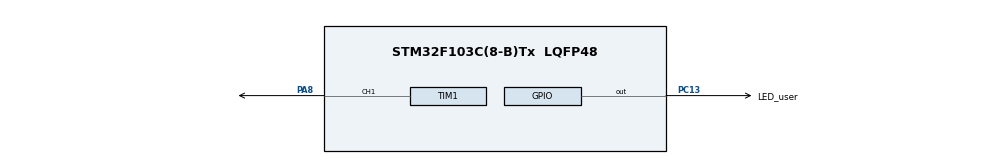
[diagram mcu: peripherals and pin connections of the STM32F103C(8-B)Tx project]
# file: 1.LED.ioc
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Mcu.Family=STM32F1
Mcu.Name=STM32F103C(8-B)Tx
Mcu.Package=LQFP48
NVIC.PriorityGroup=NVIC_PRIORITYGROUP_4
PA13.Mode=Serial_Wire
PA13.Signal=SYS_JTMS-SWDIO
PA14.Mode=Serial_Wire
PA14.Signal=SYS_JTCK-SWCLK
PA8.Signal=S_TIM1_CH1
PC13-TAMPER-RTC.GPIO_Label=LED_user
PC13-TAMPER-RTC.PinState=GPIO_PIN_SET
PC13-TAMPER-RTC.Signal=GPIO_Output
PD0-OSC_IN.Mode=HSE-External-Oscillator
PD0-OSC_IN.Signal=RCC_OSC_IN
PD1-OSC_OUT.Mode=HSE-External-Oscillator
PD1-OSC_OUT.Signal=RCC_OSC_OUT
ProjectManager.HeapSize=0x200
ProjectManager.StackSize=0x400
ProjectManager.TargetToolchain=MDK-ARM V5.32
RCC.AHBFreq_Value=72000000
RCC.APB1CLKDivider=RCC_HCLK_DIV2
RCC.APB1Freq_Value=36000000
RCC.APB1TimFreq_Value=72000000
RCC.APB2Freq_Value=72000000
RCC.APB2TimFreq_Value=72000000
RCC.HCLKFreq_Value=72000000
RCC.PLLMUL=RCC_PLL_MUL9
RCC.PLLSourceVirtual=RCC_PLLSOURCE_HSE
RCC.SYSCLKFreq_VALUE=72000000
RCC.SYSCLKSource=RCC_SYSCLKSOURCE_PLLCLK
RCC.USBFreq_Value=72000000
SH.S_TIM1_CH1.0=TIM1_CH1,PWM Generation1 CH1
TIM1.Channel-PWM\ Generation1\ CH1=TIM_CHANNEL_1
TIM1.Period=99
TIM1.Prescaler=71
VP_TIM1_VS_ClockSourceINT.Mode=Internal
board=custom

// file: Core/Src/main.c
/* USER CODE BEGIN Header */
/**
 ******************************************************************************
 * @file           : main.c
 * @brief          : Main program body
 ******************************************************************************
 * @attention
 *
 * Copyright (c) 2024 STMicroelectronics.
 * All rights reserved.
 *
 * This software is licensed under terms that can be found in the LICENSE file
 * in the root directory of this software component.
 * If no LICENSE file comes with this software, it is provided AS-IS.
 *
 ******************************************************************************
 */
/* USER CODE END Header */
#include "main.h"
#include "tim.h"
#include "gpio.h"

void SystemClock_Config(void);

int main(void)
{

  /* MCU Configuration--------------------------------------------------------*/

  /* Reset of all peripherals, Initializes the Flash interface and the Systick. */
  LL_APB2_GRP1_EnableClock(LL_APB2_GRP1_PERIPH_AFIO);
  LL_APB1_GRP1_EnableClock(LL_APB1_GRP1_PERIPH_PWR);

  /* System interrupt init*/
  NVIC_SetPriorityGrouping(NVIC_PRIORITYGROUP_4);

  /* SysTick_IRQn interrupt configuration */
  NVIC_SetPriority(SysTick_IRQn, NVIC_EncodePriority(NVIC_GetPriorityGrouping(), 15, 0));

  /** NOJTAG: JTAG-DP Disabled and SW-DP Enabled
   */
  LL_GPIO_AF_Remap_SWJ_NOJTAG();

  /* Configure the system clock */
  SystemClock_Config();

  /* Initialize all configured peripherals */
  MX_GPIO_Init();
  MX_TIM1_Init();
  /* USER CODE BEGIN 2 */
  LL_TIM_EnableCounter(TIM1);                        // 启用TIM1的计数器
  LL_TIM_CC_EnableChannel(TIM1, LL_TIM_CHANNEL_CH1); // 启用定时器的指定通道
  LL_TIM_EnableAllOutputs(TIM1);                     // 启用定时器的所有输出，经过测试，不加该语句无法输出PWM

  LL_TIM_OC_SetCompareCH1(TIM1, 50); // 使用函数输出占空比为50的PWM
  // TIM1->CCR1 = 50; // 直接写寄存器的CCR值，输出PWM
  /* USER CODE END 2 */

  /* Infinite loop */
  /* USER CODE BEGIN WHILE */
  while (1)
  {
    // 呼吸灯程序
    for (uint16_t i = 0; i <= 100; i++)
    {
      LL_TIM_OC_SetCompareCH1(TIM1, i); // 输出占空比为i的PWM
      LL_mDelay(50);
    }
    for (uint16_t i = 0; i <= 100; i++)
    {
      LL_TIM_OC_SetCompareCH1(TIM1, 100 - i);
      LL_mDelay(50);
    }
    /* USER CODE END WHILE */

  }
}

void SystemClock_Config(void)
{
  LL_FLASH_SetLatency(LL_FLASH_LATENCY_2);
  while (LL_FLASH_GetLatency() != LL_FLASH_LATENCY_2)
  {
  }
  LL_RCC_HSE_Enable();

  /* Wait till HSE is ready */
  while (LL_RCC_HSE_IsReady() != 1)
  {
  }
  LL_RCC_PLL_ConfigDomain_SYS(LL_RCC_PLLSOURCE_HSE_DIV_1, LL_RCC_PLL_MUL_9);
  LL_RCC_PLL_Enable();

  /* Wait till PLL is ready */
  while (LL_RCC_PLL_IsReady() != 1)
  {
  }
  LL_RCC_SetAHBPrescaler(LL_RCC_SYSCLK_DIV_1);
  LL_RCC_SetAPB1Prescaler(LL_RCC_APB1_DIV_2);
  LL_RCC_SetAPB2Prescaler(LL_RCC_APB2_DIV_1);
  LL_RCC_SetSysClkSource(LL_RCC_SYS_CLKSOURCE_PLL);

  /* Wait till System clock is ready */
  while (LL_RCC_GetSysClkSource() != LL_RCC_SYS_CLKSOURCE_STATUS_PLL)
  {
  }
  LL_Init1msTick(72000000);
  LL_SetSystemCoreClock(72000000);
}

void Error_Handler(void)
{
  __disable_irq();
  while (1)
  {
  }
}
